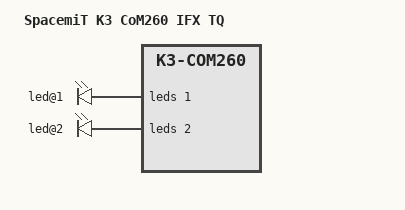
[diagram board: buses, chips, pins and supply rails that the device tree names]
// SPDX-License-Identifier: (GPL-2.0 OR MIT)
/* Copyright (c) 2026 SpacemiT (Hangzhou) Technology Co. Ltd */

#include <dt-bindings/leds/common.h>

#include "k3-com260.dtsi"

/ {
	model = "SpacemiT K3 CoM260 IFX TQ";
	compatible = "spacemit,k3-com260-ifx-tq", "spacemit,k3-com260", "spacemit,k3";

	aliases {
		serial0 = &uart0;
		ethernet0 = &eth1;
	};

	chosen {
		stdout-path = "serial0:115200n8";
	};
};

&phy1 {
	realtek,aldps-enable;
	realtek,clkout-disable;

	leds {
		#address-cells = <1>;
		#size-cells = <0>;

		led@1 {
			reg = <1>;
			function = LED_FUNCTION_LAN;
			color = <LED_COLOR_ID_GREEN>;
			default-state = "keep";
		};

		led@2 {
			reg = <2>;
			function = LED_FUNCTION_LAN;
			color = <LED_COLOR_ID_YELLOW>;
			default-state = "keep";
		};
	};
};
